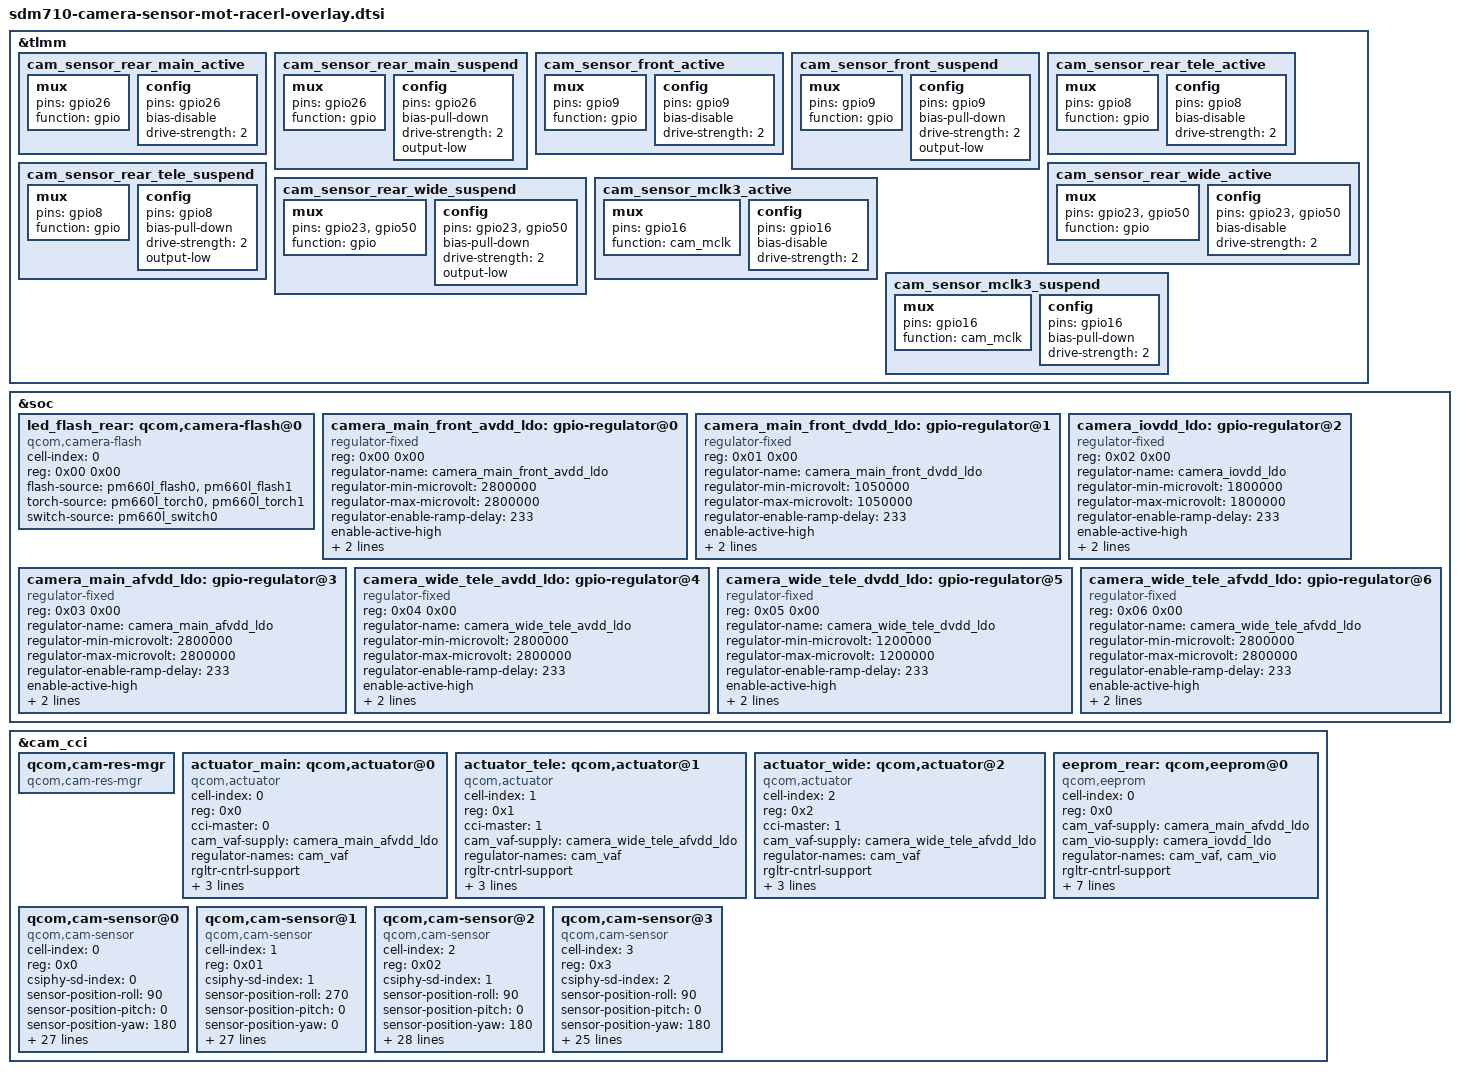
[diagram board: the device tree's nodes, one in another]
/*
 * Copyright (c) 2016-2018, The Linux Foundation. All rights reserved.
 *
 * This program is free software; you can redistribute it and/or modify
 * it under the terms of the GNU General Public License version 2 and
 * only version 2 as published by the Free Software Foundation.
 *
 * This program is distributed in the hope that it will be useful,
 * but WITHOUT ANY WARRANTY; without even the implied warranty of
 * MERCHANTABILITY or FITNESS FOR A PARTICULAR PURPOSE.  See the
 * GNU General Public License for more details.
 */

&tlmm {
	cam_sensor_rear_main_active: cam_sensor_rear_main_active {
		/* MAIN RESET active*/
		mux {
			pins = "gpio26";
			function = "gpio";
		};

		config {
			pins = "gpio26";
			bias-disable; /* No PULL */
			drive-strength = <2>; /* 2 MA */
		};
	};

	cam_sensor_rear_main_suspend: cam_sensor_rear_main_suspend {
		/* MAIN RESET suspend*/
		mux {
			pins = "gpio26";
			function = "gpio";
		};

		config {
			pins = "gpio26";
			bias-pull-down; /* PULL DOWN */
			drive-strength = <2>; /* 2 MA */
			output-low;
		};
	};

	cam_sensor_front_active: cam_sensor_front_active {
		/* FRONT RESET active*/
		mux {
			pins = "gpio9";
			function = "gpio";
		};

		config {
			pins = "gpio9";
			bias-disable; /* No PULL */
			drive-strength = <2>; /* 2 MA */
		};
	};

	cam_sensor_front_suspend: cam_sensor_front_suspend {
		/* FRONT RESET suspend*/
		mux {
			pins = "gpio9";
			function = "gpio";
		};

		config {
			pins = "gpio9";
			bias-pull-down; /* PULL DOWN */
			drive-strength = <2>; /* 2 MA */
			output-low;
		};
	};

	cam_sensor_rear_tele_active: cam_sensor_rear_tele_active {
		/* TELE RESET active*/
		mux {
			pins = "gpio8";
			function = "gpio";
		};

		config {
			pins = "gpio8";
			bias-disable; /* No PULL */
			drive-strength = <2>; /* 2 MA */
		};
	};

	cam_sensor_rear_tele_suspend: cam_sensor_rear_tele_suspend {
		/* TELE RESET suspend*/
		mux {
			pins = "gpio8";
			function = "gpio";
		};

		config {
			pins = "gpio8";
			bias-pull-down; /* PULL DOWN */
			drive-strength = <2>; /* 2 MA */
			output-low;
		};
	};

	cam_sensor_rear_wide_active: cam_sensor_rear_wide_active {
		/* WIDE RESET active*/
		mux {
			pins = "gpio23", "gpio50";
			function = "gpio";
		};

		config {
			pins = "gpio23", "gpio50";
			bias-disable; /* No PULL */
			drive-strength = <2>; /* 2 MA */
		};
	};

	cam_sensor_rear_wide_suspend: cam_sensor_rear_wide_suspend {
		/* WIDE RESET suspend*/
		mux {
			pins = "gpio23", "gpio50";
			function = "gpio";
		};

		config {
			pins = "gpio23", "gpio50";
			bias-pull-down; /* PULL DOWN */
			drive-strength = <2>; /* 2 MA */
			output-low;
		};
	};

	cam_sensor_mclk3_active: cam_sensor_mclk3_active {
		/* MCLK3 */
		mux {
			pins = "gpio16";
			function = "cam_mclk";
		};

		config {
			pins = "gpio16";
			bias-disable; /* No PULL */
			drive-strength = <2>; /* 2 MA */
		};
	};

	cam_sensor_mclk3_suspend: cam_sensor_mclk3_suspend {
		/* MCLK3 */
		mux {
			pins = "gpio16";
			function = "cam_mclk";
		};

		config {
			pins = "gpio16";
			bias-pull-down; /* PULL DOWN */
			drive-strength = <2>; /* 2 MA */
		};
	};
};

&soc {
	led_flash_rear: qcom,camera-flash@0 {
		cell-index = <0>;
		reg = <0x00 0x00>;
		compatible = "qcom,camera-flash";
		flash-source = <&pm660l_flash0 &pm660l_flash1>;
		torch-source = <&pm660l_torch0 &pm660l_torch1>;
		switch-source = <&pm660l_switch0>;
		status = "ok";
	};

	camera_main_front_avdd_ldo: gpio-regulator@0 {
		compatible = "regulator-fixed";
		reg = <0x00 0x00>;
		regulator-name = "camera_main_front_avdd_ldo";
		regulator-min-microvolt = <2800000>;
		regulator-max-microvolt = <2800000>;
		regulator-enable-ramp-delay = <233>;
		enable-active-high;
		gpio = <&pm660l_gpios 4 0>;
		vin-supply = <&pm660l_bob>;
	};

	camera_main_front_dvdd_ldo: gpio-regulator@1 {
		compatible = "regulator-fixed";
		reg = <0x01 0x00>;
		regulator-name = "camera_main_front_dvdd_ldo";
		regulator-min-microvolt = <1050000>;
		regulator-max-microvolt = <1050000>;
		regulator-enable-ramp-delay = <233>;
		enable-active-high;
		gpio = <&pm660l_gpios 3 0>;
		vin-supply = <&pm660_s6>;
	};

	camera_iovdd_ldo: gpio-regulator@2 {
		compatible = "regulator-fixed";
		reg = <0x02 0x00>;
		regulator-name = "camera_iovdd_ldo";
		regulator-min-microvolt = <1800000>;
		regulator-max-microvolt = <1800000>;
		regulator-enable-ramp-delay = <233>;
		enable-active-high;
		gpio = <&pm660l_gpios 2 0>;
		vin-supply = <&pm660_s4>;
	};

	camera_main_afvdd_ldo: gpio-regulator@3 {
		compatible = "regulator-fixed";
		reg = <0x03 0x00>;
		regulator-name = "camera_main_afvdd_ldo";
		regulator-min-microvolt = <2800000>;
		regulator-max-microvolt = <2800000>;
		regulator-enable-ramp-delay = <233>;
		enable-active-high;
		gpio = <&tlmm 27 0>;
		vin-supply = <&pm660l_bob>;
	};

	camera_wide_tele_avdd_ldo: gpio-regulator@4 {
		compatible = "regulator-fixed";
		reg = <0x04 0x00>;
		regulator-name = "camera_wide_tele_avdd_ldo";
		regulator-min-microvolt = <2800000>;
		regulator-max-microvolt = <2800000>;
		regulator-enable-ramp-delay = <233>;
		enable-active-high;
		gpio = <&tlmm 100 0>;
		vin-supply = <&pm660l_bob>;
	};

	camera_wide_tele_dvdd_ldo: gpio-regulator@5 {
		compatible = "regulator-fixed";
		reg = <0x05 0x00>;
		regulator-name = "camera_wide_tele_dvdd_ldo";
		regulator-min-microvolt = <1200000>;
		regulator-max-microvolt = <1200000>;
		regulator-enable-ramp-delay = <233>;
		enable-active-high;
		gpio = <&tlmm 119 0>;
		vin-supply = <&pm660_s6>;
	};

	camera_wide_tele_afvdd_ldo: gpio-regulator@6 {
		compatible = "regulator-fixed";
		reg = <0x06 0x00>;
		regulator-name = "camera_wide_tele_afvdd_ldo";
		regulator-min-microvolt = <2800000>;
		regulator-max-microvolt = <2800000>;
		regulator-enable-ramp-delay = <233>;
		enable-active-high;
		gpio = <&tlmm 95 0>;
		vin-supply = <&pm660l_bob>;
	};
};

&cam_cci {
	qcom,cam-res-mgr {
		compatible = "qcom,cam-res-mgr";
		status = "ok";
	};

	actuator_main: qcom,actuator@0 {
		cell-index = <0>;
		reg = <0x0>;
		compatible = "qcom,actuator";
		cci-master = <0>;
		cam_vaf-supply = <&camera_main_afvdd_ldo>;
		regulator-names = "cam_vaf";
		rgltr-cntrl-support;
		rgltr-min-voltage = <2800000>;
		rgltr-max-voltage = <2800000>;
		rgltr-load-current = <0>;
	};

	actuator_tele: qcom,actuator@1 {
		cell-index = <1>;
		reg = <0x1>;
		compatible = "qcom,actuator";
		cci-master = <1>;
		cam_vaf-supply = <&camera_wide_tele_afvdd_ldo>;
		regulator-names = "cam_vaf";
		rgltr-cntrl-support;
		rgltr-min-voltage = <2800000>;
		rgltr-max-voltage = <2800000>;
		rgltr-load-current = <0>;
	};

	actuator_wide: qcom,actuator@2 {
		cell-index = <2>;
		reg = <0x2>;
		compatible = "qcom,actuator";
		cci-master = <1>;
		cam_vaf-supply = <&camera_wide_tele_afvdd_ldo>;
		regulator-names = "cam_vaf";
		rgltr-cntrl-support;
		rgltr-min-voltage = <2800000>;
		rgltr-max-voltage = <2800000>;
		rgltr-load-current = <0>;
	};

	eeprom_rear: qcom,eeprom@0 {
		cell-index = <0>;
		reg = <0x0>;
		compatible = "qcom,eeprom";
		cam_vaf-supply = <&camera_main_afvdd_ldo>;
		cam_vio-supply = <&camera_iovdd_ldo>;
		regulator-names = "cam_vaf", "cam_vio";
		rgltr-cntrl-support;
		rgltr-min-voltage = <2800000 1800000>;
		rgltr-max-voltage = <2800000 1800000>;
		rgltr-load-current = <0 0>;
		cci-master = <0>;
		status = "ok";
		clocks = <&clock_camcc CAM_CC_MCLK0_CLK>;
		clock-names = "cam_clk";
		clock-cntl-level = "turbo";
		clock-rates = <24000000>;
	};

	qcom,cam-sensor@0 {
		cell-index = <0>;
		compatible = "qcom,cam-sensor";
		reg = <0x0>;
		csiphy-sd-index = <0>;
		sensor-position-roll = <90>;
		sensor-position-pitch = <0>;
		sensor-position-yaw = <180>;
		eeprom-src = <&eeprom_rear>;
		led-flash-src = <&led_flash_rear>;
		actuator-src = <&actuator_main>;
		cam_vio-supply = <&camera_iovdd_ldo>;
		cam_vana-supply = <&camera_main_front_avdd_ldo>;
		cam_vdig-supply = <&camera_main_front_dvdd_ldo>;
		cam_clk-supply = <&titan_top_gdsc>;
		regulator-names = "cam_vio", "cam_vana", "cam_vdig", "cam_clk";
		rgltr-cntrl-support;
		rgltr-min-voltage = <1800000 2800000 1050000 0>;
		rgltr-max-voltage = <1800000 2800000 1050000 0>;
		rgltr-load-current = <0 80000 105000 0>;
		gpio-no-mux = <0>;
		pinctrl-names = "cam_default", "cam_suspend";
		pinctrl-0 = <&cam_sensor_mclk0_active
				&cam_sensor_rear_main_active>;
		pinctrl-1 = <&cam_sensor_mclk0_suspend
				&cam_sensor_rear_main_suspend>;
		gpios = <&tlmm 13 0>,
			<&tlmm 26 0>;
		gpio-reset = <1>;
		gpio-req-tbl-num = <0 1>;
		gpio-req-tbl-flags = <1 0>;
		gpio-req-tbl-label = "CAMIF_MCLK0",
					"CAM_RESET0";
		cci-master = <0>;
		status = "ok";
		clocks = <&clock_camcc CAM_CC_MCLK0_CLK>;
		clock-names = "cam_clk";
		clock-cntl-level = "turbo";
		clock-rates = <24000000>;
	};

	qcom,cam-sensor@1 {
		cell-index = <1>;
		compatible = "qcom,cam-sensor";
		reg = <0x01>;
		csiphy-sd-index = <1>;
		sensor-position-roll = <270>;
		sensor-position-pitch = <0>;
		sensor-position-yaw = <0>;
		cam_vio-supply = <&camera_iovdd_ldo>;
		cam_vana-supply = <&camera_main_front_avdd_ldo>;
		cam_vdig-supply = <&camera_main_front_dvdd_ldo>;
		cam_clk-supply = <&titan_top_gdsc>;
		regulator-names = "cam_vio", "cam_vana", "cam_vdig", "cam_clk";
		rgltr-cntrl-support;
		rgltr-min-voltage = <1800000 2800000 1050000 0>;
		rgltr-max-voltage = <1800000 2800000 1050000 0>;
		rgltr-load-current = <0 80000 105000 0>;
		gpio-no-mux = <0>;
		pinctrl-names = "cam_default", "cam_suspend";
		pinctrl-0 = <&cam_sensor_mclk2_active
				&cam_sensor_front_active>;
		pinctrl-1 = <&cam_sensor_mclk2_suspend
				&cam_sensor_front_suspend>;
		gpios = <&tlmm 15 0>,
			<&tlmm 9 0>,
			<&tlmm 50 0>;
		gpio-reset= <1>;
		gpio-custom1= <2>;
		gpio-req-tbl-num = <0 1 2>;
		gpio-req-tbl-flags = <1 0 0>;
		gpio-req-tbl-label = "CAMIF_MCLK2",
				"CAM_RESET2",
				"CAM_SWT1";
		sensor-mode = <1>;
		cci-master = <0>;
		status = "ok";
		clocks = <&clock_camcc CAM_CC_MCLK2_CLK>;
		clock-names = "cam_clk";
		clock-cntl-level = "turbo";
		clock-rates = <24000000>;
	};

	qcom,cam-sensor@2 {
		cell-index = <2>;
		compatible = "qcom,cam-sensor";
		reg = <0x02>;
		csiphy-sd-index = <1>;
		sensor-position-roll = <90>;
		sensor-position-pitch = <0>;
		sensor-position-yaw = <180>;
		actuator-src = <&actuator_wide>;
		cam_vio-supply = <&camera_iovdd_ldo>;
		cam_vana-supply = <&camera_wide_tele_avdd_ldo>;
		cam_vdig-supply = <&camera_wide_tele_dvdd_ldo>;
		cam_clk-supply = <&titan_top_gdsc>;
		regulator-names = "cam_vio", "cam_vana", "cam_vdig", "cam_clk";
		rgltr-cntrl-support;
		rgltr-min-voltage = <1800000 2800000 1200000 0>;
		rgltr-max-voltage = <1800000 2800000 1200000 0>;
		rgltr-load-current = <0 80000 105000 0>;
		gpio-no-mux = <0>;
		pinctrl-names = "cam_default", "cam_suspend";
		pinctrl-0 = <&cam_sensor_mclk3_active
				&cam_sensor_rear_wide_active>;
		pinctrl-1 = <&cam_sensor_mclk3_suspend
				&cam_sensor_rear_wide_suspend>;
		gpios = <&tlmm 16 0>,
			<&tlmm 23 0>,
			<&tlmm 50 0>;
		gpio-reset= <1>;
		gpio-custom1= <2>;
		gpio-req-tbl-num = <0 1 2>;
		gpio-req-tbl-flags = <1 0 0>;
		gpio-req-tbl-label = "CAMIF_MCLK3",
				"CAM_RESET3",
				"CAM_SWT2";
		sensor-mode = <0>;
		cci-master = <1>;
		status = "ok";
		clocks = <&clock_camcc CAM_CC_MCLK3_CLK>;
		clock-names = "cam_clk";
		clock-cntl-level = "turbo";
		clock-rates = <24000000>;
	};

	qcom,cam-sensor@3 {
		cell-index = <3>;
		compatible = "qcom,cam-sensor";
		reg = <0x3>;
		csiphy-sd-index = <2>;
		sensor-position-roll = <90>;
		sensor-position-pitch = <0>;
		sensor-position-yaw = <180>;
		actuator-src = <&actuator_tele>;
		cam_vio-supply = <&camera_iovdd_ldo>;
		cam_vana-supply = <&camera_wide_tele_avdd_ldo>;
		cam_vdig-supply = <&camera_wide_tele_dvdd_ldo>;
		cam_clk-supply = <&titan_top_gdsc>;
		regulator-names = "cam_vio", "cam_vana", "cam_vdig", "cam_clk";
		rgltr-cntrl-support;
		rgltr-min-voltage = <1800000 2800000 1200000 0>;
		rgltr-max-voltage = <1800000 2800000 1200000 0>;
		rgltr-load-current = <0 80000 105000 0>;
		gpio-no-mux = <0>;
		pinctrl-names = "cam_default", "cam_suspend";
		pinctrl-0 = <&cam_sensor_mclk1_active
				&cam_sensor_rear_tele_active>;
		pinctrl-1 = <&cam_sensor_mclk1_suspend
				&cam_sensor_rear_tele_suspend>;
		gpios = <&tlmm 14 0>,
			<&tlmm 8 0>;
		gpio-reset = <1>;
		gpio-req-tbl-num = <0 1>;
		gpio-req-tbl-flags = <1 0>;
		gpio-req-tbl-label = "CAMIF_MCLK1",
					"CAM_RESET1";
		cci-master = <1>;
		status = "ok";
		clocks = <&clock_camcc CAM_CC_MCLK1_CLK>;
		clock-names = "cam_clk";
		clock-cntl-level = "turbo";
		clock-rates = <24000000>;
	};
};

